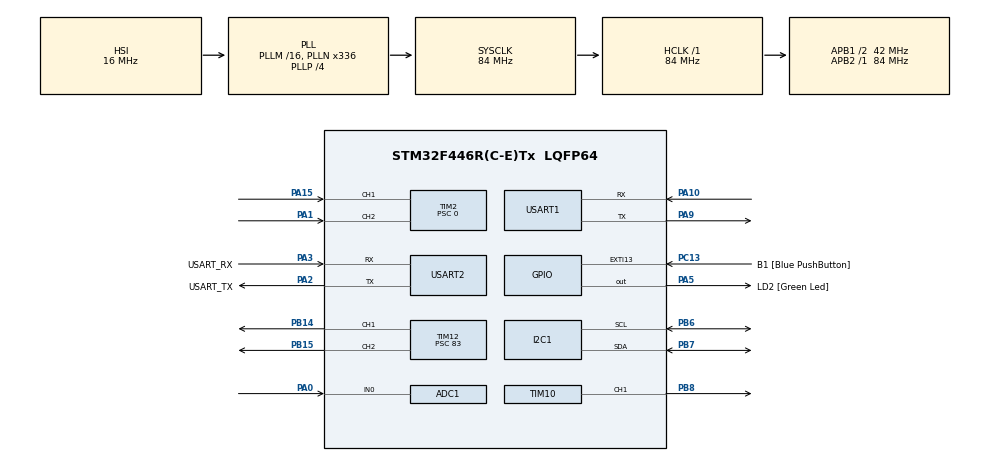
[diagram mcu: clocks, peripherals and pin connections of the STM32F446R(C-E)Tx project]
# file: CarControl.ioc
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ADC1.Channel-0\#ChannelRegularConversion=ADC_CHANNEL_0
ADC1.ContinuousConvMode=DISABLE
ADC1.ExternalTrigConv=ADC_EXTERNALTRIGCONV_T3_TRGO
ADC1.NbrOfConversionFlag=1
ADC1.Rank-0\#ChannelRegularConversion=1
ADC1.SamplingTime-0\#ChannelRegularConversion=ADC_SAMPLETIME_3CYCLES
ADC1.master=1
Dma.ADC1.0.Direction=DMA_PERIPH_TO_MEMORY
Dma.ADC1.0.FIFOMode=DMA_FIFOMODE_DISABLE
Dma.ADC1.0.Instance=DMA2_Stream0
Dma.ADC1.0.MemDataAlignment=DMA_MDATAALIGN_HALFWORD
Dma.ADC1.0.MemInc=DMA_MINC_ENABLE
Dma.ADC1.0.Mode=DMA_CIRCULAR
Dma.ADC1.0.PeriphDataAlignment=DMA_PDATAALIGN_HALFWORD
Dma.ADC1.0.PeriphInc=DMA_PINC_DISABLE
Dma.ADC1.0.Priority=DMA_PRIORITY_LOW
Dma.Request0=ADC1
Dma.Request1=USART1_RX
Dma.Request2=USART1_TX
Dma.USART1_RX.1.Direction=DMA_PERIPH_TO_MEMORY
Dma.USART1_RX.1.FIFOMode=DMA_FIFOMODE_DISABLE
Dma.USART1_RX.1.Instance=DMA2_Stream2
Dma.USART1_RX.1.MemDataAlignment=DMA_MDATAALIGN_BYTE
Dma.USART1_RX.1.MemInc=DMA_MINC_ENABLE
Dma.USART1_RX.1.Mode=DMA_CIRCULAR
Dma.USART1_RX.1.PeriphDataAlignment=DMA_PDATAALIGN_BYTE
Dma.USART1_RX.1.PeriphInc=DMA_PINC_DISABLE
Dma.USART1_RX.1.Priority=DMA_PRIORITY_HIGH
Dma.USART1_TX.2.Direction=DMA_MEMORY_TO_PERIPH
Dma.USART1_TX.2.FIFOMode=DMA_FIFOMODE_DISABLE
Dma.USART1_TX.2.Instance=DMA2_Stream7
Dma.USART1_TX.2.MemDataAlignment=DMA_MDATAALIGN_BYTE
Dma.USART1_TX.2.MemInc=DMA_MINC_ENABLE
Dma.USART1_TX.2.Mode=DMA_NORMAL
Dma.USART1_TX.2.PeriphDataAlignment=DMA_PDATAALIGN_BYTE
Dma.USART1_TX.2.PeriphInc=DMA_PINC_DISABLE
Dma.USART1_TX.2.Priority=DMA_PRIORITY_HIGH
FREERTOS.Tasks01=defaultTask,24,128,RunDefaultTask,Default,NULL,Dynamic,NULL,NULL;ControlTask,40,512,RunControlTask,Default,NULL,Dynamic,NULL,NULL;SensorTask,24,512,RunSensorTask,Default,NULL,Dynamic,NULL,NULL;StatusTask,8,512,RunStatusTask,Default,NULL,Dynamic,NULL,NULL;microROSTask,24,1024,RunMicroROSTask,Default,NULL,Dynamic,NULL,NULL
FREERTOS.configENABLE_FPU=1
FREERTOS.configTOTAL_HEAP_SIZE=32768
FREERTOS.configUSE_NEWLIB_REENTRANT=1
Mcu.Family=STM32F4
Mcu.Name=STM32F446R(C-E)Tx
Mcu.Package=LQFP64
NVIC.DMA2_Stream0_IRQn=true\:5\:0\:false\:false\:true\:true\:false\:true\:true
NVIC.DMA2_Stream2_IRQn=true\:5\:0\:false\:false\:true\:true\:false\:true\:true
NVIC.DMA2_Stream7_IRQn=true\:5\:0\:false\:false\:true\:true\:false\:true\:true
NVIC.PriorityGroup=NVIC_PRIORITYGROUP_4
NVIC.TIM3_IRQn=true\:5\:0\:false\:false\:true\:true\:true\:true\:true
NVIC.TIM6_DAC_IRQn=true\:15\:0\:false\:false\:true\:false\:false\:true\:true
NVIC.TimeBase=TIM6_DAC_IRQn
NVIC.TimeBaseIP=TIM6
NVIC.USART1_IRQn=true\:5\:0\:false\:false\:true\:true\:true\:true\:true
PA0-WKUP.Signal=ADCx_IN0
PA1.Signal=S_TIM2_CH2
PA10.Mode=Asynchronous
PA10.Signal=USART1_RX
PA13.GPIO_Label=TMS
PA13.Mode=Serial_Wire
PA13.Signal=SYS_JTMS-SWDIO
PA14.GPIO_Label=TCK
PA14.Mode=Serial_Wire
PA14.Signal=SYS_JTCK-SWCLK
PA15.Signal=S_TIM2_CH1_ETR
PA2.GPIO_Label=USART_TX
PA2.Mode=Asynchronous
PA2.Signal=USART2_TX
PA3.GPIO_Label=USART_RX
PA3.Mode=Asynchronous
PA3.Signal=USART2_RX
PA5.GPIO_Label=LD2 [Green Led]
PA5.Signal=GPIO_Output
PA9.Mode=Asynchronous
PA9.Signal=USART1_TX
PB14.Signal=S_TIM12_CH1
PB15.Signal=S_TIM12_CH2
PB3.GPIO_Label=SWO
PB3.Signal=SYS_JTDO-SWO
PB6.Mode=I2C
PB6.Signal=I2C1_SCL
PB7.Mode=I2C
PB7.Signal=I2C1_SDA
PB8.Signal=S_TIM10_CH1
PC13.GPIO_Label=B1 [Blue PushButton]
PC13.GPIO_ModeDefaultEXTI=GPIO_MODE_IT_FALLING
PC13.Signal=GPXTI13
PC14-OSC32_IN.Mode=LSE-External-Oscillator
PC14-OSC32_IN.Signal=RCC_OSC32_IN
PC15-OSC32_OUT.Mode=LSE-External-Oscillator
PC15-OSC32_OUT.Signal=RCC_OSC32_OUT
PH0-OSC_IN.Mode=HSE-External-Oscillator
PH0-OSC_IN.Signal=RCC_OSC_IN
PH1-OSC_OUT.Mode=HSE-External-Oscillator
PH1-OSC_OUT.Signal=RCC_OSC_OUT
ProjectManager.HeapSize=0x200
ProjectManager.StackSize=0x400
ProjectManager.TargetToolchain=Makefile
RCC.48MHZClocksFreq_Value=84000000
RCC.AHBFreq_Value=84000000
RCC.APB1CLKDivider=RCC_HCLK_DIV2
RCC.APB1Freq_Value=42000000
RCC.APB1TimFreq_Value=84000000
RCC.APB2Freq_Value=84000000
RCC.APB2TimFreq_Value=84000000
RCC.CortexFreq_Value=84000000
RCC.FLatency-AdvancedSettings=FLASH_LATENCY_2
RCC.HCLKFreq_Value=84000000
RCC.HSE_VALUE=8000000
RCC.HSI_VALUE=16000000
RCC.PLLN=336
RCC.PLLP=RCC_PLLP_DIV4
RCC.SYSCLKFreq_VALUE=84000000
RCC.SYSCLKSource=RCC_SYSCLKSOURCE_PLLCLK
RCC.USBFreq_Value=168000000
RCC.VCOOutputFreq_Value=336000000
SH.ADCx_IN0.0=ADC1_IN0,IN0
SH.S_TIM10_CH1.0=TIM10_CH1,PWM Generation1 CH1
SH.S_TIM12_CH1.0=TIM12_CH1,PWM Generation1 CH1
SH.S_TIM12_CH2.0=TIM12_CH2,PWM Generation2 CH2
SH.S_TIM2_CH1_ETR.0=TIM2_CH1,Encoder_Interface
SH.S_TIM2_CH2.0=TIM2_CH2,Encoder_Interface
TIM10.Channel=TIM_CHANNEL_1
TIM10.Period=49
TIM10.Prescaler=83
TIM10.Pulse=0
TIM12.Channel-PWM\ Generation1\ CH1=TIM_CHANNEL_1
TIM12.Channel-PWM\ Generation2\ CH2=TIM_CHANNEL_2
TIM12.Period=49
TIM12.Prescaler=83
TIM2.EncoderMode=TIM_ENCODERMODE_TI12
TIM2.Period=1000
TIM2.Prescaler=0
TIM3.Channel-Output\ Compare1\ No\ Output=TIM_CHANNEL_1
TIM3.Period=999
TIM3.Prescaler=839
TIM3.TIM_MasterOutputTrigger=TIM_TRGO_UPDATE
USART1.VirtualMode=VM_ASYNC
USART2.VirtualMode=VM_ASYNC
VP_FREERTOS_VS_CMSIS_V2.Mode=CMSIS_V2
VP_SYS_VS_tim6.Mode=TIM6
VP_TIM10_VS_ClockSourceINT.Mode=Enable_Timer
VP_TIM3_VS_ClockSourceINT.Mode=Internal
VP_TIM3_VS_no_output1.Mode=Output Compare1 No Output
board=NUCLEO-F446RE

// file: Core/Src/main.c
/* USER CODE BEGIN Header */
/**
  ******************************************************************************
  * @file           : main.c
  * @brief          : Main program body
  ******************************************************************************
  * @attention
  *
  * Copyright (c) 2026 STMicroelectronics.
  * All rights reserved.
  *
  * This software is licensed under terms that can be found in the LICENSE file
  * in the root directory of this software component.
  * If no LICENSE file comes with this software, it is provided AS-IS.
  *
  ******************************************************************************
  */
/* USER CODE END Header */
#include "main.h"
#include "cmsis_os.h"

/* USER CODE BEGIN Includes */
#include "mros.h"
#include "main_app.hpp"
/* USER CODE END Includes */

ADC_HandleTypeDef hadc1;
DMA_HandleTypeDef hdma_adc1;

I2C_HandleTypeDef hi2c1;

TIM_HandleTypeDef htim2;
TIM_HandleTypeDef htim3;
TIM_HandleTypeDef htim10;
TIM_HandleTypeDef htim12;

UART_HandleTypeDef huart1;
UART_HandleTypeDef huart2;
DMA_HandleTypeDef hdma_usart1_rx;
DMA_HandleTypeDef hdma_usart1_tx;

/* Definitions for defaultTask */
osThreadId_t defaultTaskHandle;
const osThreadAttr_t defaultTask_attributes = {
  .name = "defaultTask",
  .stack_size = 128 * 4,
  .priority = (osPriority_t) osPriorityNormal,
};
/* Definitions for ControlTask */
osThreadId_t ControlTaskHandle;
const osThreadAttr_t ControlTask_attributes = {
  .name = "ControlTask",
  .stack_size = 512 * 4,
  .priority = (osPriority_t) osPriorityHigh,
};
/* Definitions for SensorTask */
osThreadId_t SensorTaskHandle;
const osThreadAttr_t SensorTask_attributes = {
  .name = "SensorTask",
  .stack_size = 512 * 4,
  .priority = (osPriority_t) osPriorityNormal,
};
/* Definitions for StatusTask */
osThreadId_t StatusTaskHandle;
const osThreadAttr_t StatusTask_attributes = {
  .name = "StatusTask",
  .stack_size = 512 * 4,
  .priority = (osPriority_t) osPriorityLow,
};
/* Definitions for microROSTask */
osThreadId_t microROSTaskHandle;
const osThreadAttr_t microROSTask_attributes = {
  .name = "microROSTask",
  .stack_size = 1024 * 4,
  .priority = (osPriority_t) osPriorityNormal,
};

void SystemClock_Config(void);
static void MX_GPIO_Init(void);
static void MX_DMA_Init(void);
static void MX_I2C1_Init(void);
static void MX_USART2_UART_Init(void);
static void MX_TIM3_Init(void);
static void MX_TIM2_Init(void);
static void MX_TIM10_Init(void);
static void MX_TIM12_Init(void);
static void MX_ADC1_Init(void);
static void MX_USART1_UART_Init(void);
void RunDefaultTask(void *argument);
void RunControlTask(void *argument);
void RunSensorTask(void *argument);
void RunStatusTask(void *argument);
void RunMicroROSTask(void *argument);

int main(void)
{

  /* MCU Configuration--------------------------------------------------------*/

  /* Reset of all peripherals, Initializes the Flash interface and the Systick. */
  HAL_Init();

  /* Configure the system clock */
  SystemClock_Config();

  /* Initialize all configured peripherals */
  MX_GPIO_Init();
  MX_DMA_Init();
  MX_I2C1_Init();
  MX_USART2_UART_Init();
  MX_TIM3_Init();
  MX_TIM2_Init();
  MX_TIM10_Init();
  MX_TIM12_Init();
  MX_ADC1_Init();
  MX_USART1_UART_Init();

  /* Init scheduler */
  osKernelInitialize();

  /* USER CODE BEGIN RTOS_MUTEX */
  main_init();
  /* add mutexes, ... */
  /* USER CODE END RTOS_MUTEX */

  /* Create the thread(s) */
  /* creation of defaultTask */
  defaultTaskHandle = osThreadNew(RunDefaultTask, NULL, &defaultTask_attributes);

  /* creation of ControlTask */
  ControlTaskHandle = osThreadNew(RunControlTask, NULL, &ControlTask_attributes);

  /* creation of SensorTask */
  SensorTaskHandle = osThreadNew(RunSensorTask, NULL, &SensorTask_attributes);

  /* creation of StatusTask */
  StatusTaskHandle = osThreadNew(RunStatusTask, NULL, &StatusTask_attributes);

  /* creation of microROSTask */
  microROSTaskHandle = osThreadNew(RunMicroROSTask, NULL, &microROSTask_attributes);

  /* Start scheduler */
  osKernelStart();

  /* We should never get here as control is now taken by the scheduler */

  /* Infinite loop */
  while (1)
  {

  }
}

void SystemClock_Config(void)
{
  RCC_OscInitTypeDef RCC_OscInitStruct = {0};
  RCC_ClkInitTypeDef RCC_ClkInitStruct = {0};

  /** Configure the main internal regulator output voltage
  */
  __HAL_RCC_PWR_CLK_ENABLE();
  __HAL_PWR_VOLTAGESCALING_CONFIG(PWR_REGULATOR_VOLTAGE_SCALE3);

  /** Initializes the RCC Oscillators according to the specified parameters
  * in the RCC_OscInitTypeDef structure.
  */
  RCC_OscInitStruct.OscillatorType = RCC_OSCILLATORTYPE_HSI;
  RCC_OscInitStruct.HSIState = RCC_HSI_ON;
  RCC_OscInitStruct.HSICalibrationValue = RCC_HSICALIBRATION_DEFAULT;
  RCC_OscInitStruct.PLL.PLLState = RCC_PLL_ON;
  RCC_OscInitStruct.PLL.PLLSource = RCC_PLLSOURCE_HSI;
  RCC_OscInitStruct.PLL.PLLM = 16;
  RCC_OscInitStruct.PLL.PLLN = 336;
  RCC_OscInitStruct.PLL.PLLP = RCC_PLLP_DIV4;
  RCC_OscInitStruct.PLL.PLLQ = 2;
  RCC_OscInitStruct.PLL.PLLR = 2;
  if (HAL_RCC_OscConfig(&RCC_OscInitStruct) != HAL_OK)
  {
    Error_Handler();
  }

  /** Initializes the CPU, AHB and APB buses clocks
  */
  RCC_ClkInitStruct.ClockType = RCC_CLOCKTYPE_HCLK|RCC_CLOCKTYPE_SYSCLK
                              |RCC_CLOCKTYPE_PCLK1|RCC_CLOCKTYPE_PCLK2;
  RCC_ClkInitStruct.SYSCLKSource = RCC_SYSCLKSOURCE_PLLCLK;
  RCC_ClkInitStruct.AHBCLKDivider = RCC_SYSCLK_DIV1;
  RCC_ClkInitStruct.APB1CLKDivider = RCC_HCLK_DIV2;
  RCC_ClkInitStruct.APB2CLKDivider = RCC_HCLK_DIV1;

  if (HAL_RCC_ClockConfig(&RCC_ClkInitStruct, FLASH_LATENCY_2) != HAL_OK)
  {
    Error_Handler();
  }
}

static void MX_ADC1_Init(void)
{

  ADC_ChannelConfTypeDef sConfig = {0};

  /** Configure the global features of the ADC (Clock, Resolution, Data Alignment and number of conversion)
  */
  hadc1.Instance = ADC1;
  hadc1.Init.ClockPrescaler = ADC_CLOCK_SYNC_PCLK_DIV4;
  hadc1.Init.Resolution = ADC_RESOLUTION_12B;
  hadc1.Init.ScanConvMode = DISABLE;
  hadc1.Init.ContinuousConvMode = DISABLE;
  hadc1.Init.DiscontinuousConvMode = DISABLE;
  hadc1.Init.ExternalTrigConvEdge = ADC_EXTERNALTRIGCONVEDGE_RISING;
  hadc1.Init.ExternalTrigConv = ADC_EXTERNALTRIGCONV_T3_TRGO;
  hadc1.Init.DataAlign = ADC_DATAALIGN_RIGHT;
  hadc1.Init.NbrOfConversion = 1;
  hadc1.Init.DMAContinuousRequests = DISABLE;
  hadc1.Init.EOCSelection = ADC_EOC_SINGLE_CONV;
  if (HAL_ADC_Init(&hadc1) != HAL_OK)
  {
    Error_Handler();
  }

  /** Configure for the selected ADC regular channel its corresponding rank in the sequencer and its sample time.
  */
  sConfig.Channel = ADC_CHANNEL_0;
  sConfig.Rank = 1;
  sConfig.SamplingTime = ADC_SAMPLETIME_3CYCLES;
  if (HAL_ADC_ConfigChannel(&hadc1, &sConfig) != HAL_OK)
  {
    Error_Handler();
  }

}

static void MX_I2C1_Init(void)
{

  hi2c1.Instance = I2C1;
  hi2c1.Init.ClockSpeed = 100000;
  hi2c1.Init.DutyCycle = I2C_DUTYCYCLE_2;
  hi2c1.Init.OwnAddress1 = 0;
  hi2c1.Init.AddressingMode = I2C_ADDRESSINGMODE_7BIT;
  hi2c1.Init.DualAddressMode = I2C_DUALADDRESS_DISABLE;
  hi2c1.Init.OwnAddress2 = 0;
  hi2c1.Init.GeneralCallMode = I2C_GENERALCALL_DISABLE;
  hi2c1.Init.NoStretchMode = I2C_NOSTRETCH_DISABLE;
  if (HAL_I2C_Init(&hi2c1) != HAL_OK)
  {
    Error_Handler();
  }

}

static void MX_TIM2_Init(void)
{

  TIM_Encoder_InitTypeDef sConfig = {0};
  TIM_MasterConfigTypeDef sMasterConfig = {0};

  htim2.Instance = TIM2;
  htim2.Init.Prescaler = 0;
  htim2.Init.CounterMode = TIM_COUNTERMODE_UP;
  htim2.Init.Period = 1000;
  htim2.Init.ClockDivision = TIM_CLOCKDIVISION_DIV1;
  htim2.Init.AutoReloadPreload = TIM_AUTORELOAD_PRELOAD_DISABLE;
  sConfig.EncoderMode = TIM_ENCODERMODE_TI12;
  sConfig.IC1Polarity = TIM_ICPOLARITY_RISING;
  sConfig.IC1Selection = TIM_ICSELECTION_DIRECTTI;
  sConfig.IC1Prescaler = TIM_ICPSC_DIV1;
  sConfig.IC1Filter = 0;
  sConfig.IC2Polarity = TIM_ICPOLARITY_RISING;
  sConfig.IC2Selection = TIM_ICSELECTION_DIRECTTI;
  sConfig.IC2Prescaler = TIM_ICPSC_DIV1;
  sConfig.IC2Filter = 0;
  if (HAL_TIM_Encoder_Init(&htim2, &sConfig) != HAL_OK)
  {
    Error_Handler();
  }
  sMasterConfig.MasterOutputTrigger = TIM_TRGO_RESET;
  sMasterConfig.MasterSlaveMode = TIM_MASTERSLAVEMODE_DISABLE;
  if (HAL_TIMEx_MasterConfigSynchronization(&htim2, &sMasterConfig) != HAL_OK)
  {
    Error_Handler();
  }

}

static void MX_TIM3_Init(void)
{

  TIM_ClockConfigTypeDef sClockSourceConfig = {0};
  TIM_MasterConfigTypeDef sMasterConfig = {0};
  TIM_OC_InitTypeDef sConfigOC = {0};

  htim3.Instance = TIM3;
  htim3.Init.Prescaler = 839;
  htim3.Init.CounterMode = TIM_COUNTERMODE_UP;
  htim3.Init.Period = 999;
  htim3.Init.ClockDivision = TIM_CLOCKDIVISION_DIV1;
  htim3.Init.AutoReloadPreload = TIM_AUTORELOAD_PRELOAD_DISABLE;
  if (HAL_TIM_Base_Init(&htim3) != HAL_OK)
  {
    Error_Handler();
  }
  sClockSourceConfig.ClockSource = TIM_CLOCKSOURCE_INTERNAL;
  if (HAL_TIM_ConfigClockSource(&htim3, &sClockSourceConfig) != HAL_OK)
  {
    Error_Handler();
  }
  if (HAL_TIM_OC_Init(&htim3) != HAL_OK)
  {
    Error_Handler();
  }
  sMasterConfig.MasterOutputTrigger = TIM_TRGO_UPDATE;
  sMasterConfig.MasterSlaveMode = TIM_MASTERSLAVEMODE_DISABLE;
  if (HAL_TIMEx_MasterConfigSynchronization(&htim3, &sMasterConfig) != HAL_OK)
  {
    Error_Handler();
  }
  sConfigOC.OCMode = TIM_OCMODE_TIMING;
  sConfigOC.Pulse = 0;
  sConfigOC.OCPolarity = TIM_OCPOLARITY_HIGH;
  sConfigOC.OCFastMode = TIM_OCFAST_DISABLE;
  if (HAL_TIM_OC_ConfigChannel(&htim3, &sConfigOC, TIM_CHANNEL_1) != HAL_OK)
  {
    Error_Handler();
  }

}

static void MX_TIM10_Init(void)
{

  TIM_OC_InitTypeDef sConfigOC = {0};

  htim10.Instance = TIM10;
  htim10.Init.Prescaler = 83;
  htim10.Init.CounterMode = TIM_COUNTERMODE_UP;
  htim10.Init.Period = 49;
  htim10.Init.ClockDivision = TIM_CLOCKDIVISION_DIV1;
  htim10.Init.AutoReloadPreload = TIM_AUTORELOAD_PRELOAD_DISABLE;
  if (HAL_TIM_Base_Init(&htim10) != HAL_OK)
  {
    Error_Handler();
  }
  if (HAL_TIM_PWM_Init(&htim10) != HAL_OK)
  {
    Error_Handler();
  }
  sConfigOC.OCMode = TIM_OCMODE_PWM1;
  sConfigOC.Pulse = 0;
  sConfigOC.OCPolarity = TIM_OCPOLARITY_HIGH;
  sConfigOC.OCFastMode = TIM_OCFAST_DISABLE;
  if (HAL_TIM_PWM_ConfigChannel(&htim10, &sConfigOC, TIM_CHANNEL_1) != HAL_OK)
  {
    Error_Handler();
  }
  HAL_TIM_MspPostInit(&htim10);

}

static void MX_TIM12_Init(void)
{

  TIM_OC_InitTypeDef sConfigOC = {0};

  htim12.Instance = TIM12;
  htim12.Init.Prescaler = 83;
  htim12.Init.CounterMode = TIM_COUNTERMODE_UP;
  htim12.Init.Period = 49;
  htim12.Init.ClockDivision = TIM_CLOCKDIVISION_DIV1;
  htim12.Init.AutoReloadPreload = TIM_AUTORELOAD_PRELOAD_DISABLE;
  if (HAL_TIM_PWM_Init(&htim12) != HAL_OK)
  {
    Error_Handler();
  }
  sConfigOC.OCMode = TIM_OCMODE_PWM1;
  sConfigOC.Pulse = 0;
  sConfigOC.OCPolarity = TIM_OCPOLARITY_HIGH;
  sConfigOC.OCFastMode = TIM_OCFAST_DISABLE;
  if (HAL_TIM_PWM_ConfigChannel(&htim12, &sConfigOC, TIM_CHANNEL_1) != HAL_OK)
  {
    Error_Handler();
  }
  if (HAL_TIM_PWM_ConfigChannel(&htim12, &sConfigOC, TIM_CHANNEL_2) != HAL_OK)
  {
    Error_Handler();
  }
  HAL_TIM_MspPostInit(&htim12);

}

static void MX_USART1_UART_Init(void)
{

  huart1.Instance = USART1;
  huart1.Init.BaudRate = 115200;
  huart1.Init.WordLength = UART_WORDLENGTH_8B;
  huart1.Init.StopBits = UART_STOPBITS_1;
  huart1.Init.Parity = UART_PARITY_NONE;
  huart1.Init.Mode = UART_MODE_TX_RX;
  huart1.Init.HwFlowCtl = UART_HWCONTROL_NONE;
  huart1.Init.OverSampling = UART_OVERSAMPLING_16;
  if (HAL_UART_Init(&huart1) != HAL_OK)
  {
    Error_Handler();
  }

}

static void MX_USART2_UART_Init(void)
{

  huart2.Instance = USART2;
  huart2.Init.BaudRate = 115200;
  huart2.Init.WordLength = UART_WORDLENGTH_8B;
  huart2.Init.StopBits = UART_STOPBITS_1;
  huart2.Init.Parity = UART_PARITY_NONE;
  huart2.Init.Mode = UART_MODE_TX_RX;
  huart2.Init.HwFlowCtl = UART_HWCONTROL_NONE;
  huart2.Init.OverSampling = UART_OVERSAMPLING_16;
  if (HAL_UART_Init(&huart2) != HAL_OK)
  {
    Error_Handler();
  }

}

static void MX_DMA_Init(void)
{

  /* DMA controller clock enable */
  __HAL_RCC_DMA2_CLK_ENABLE();

  /* DMA interrupt init */
  /* DMA2_Stream0_IRQn interrupt configuration */
  HAL_NVIC_SetPriority(DMA2_Stream0_IRQn, 5, 0);
  HAL_NVIC_EnableIRQ(DMA2_Stream0_IRQn);
  /* DMA2_Stream2_IRQn interrupt configuration */
  HAL_NVIC_SetPriority(DMA2_Stream2_IRQn, 5, 0);
  HAL_NVIC_EnableIRQ(DMA2_Stream2_IRQn);
  /* DMA2_Stream7_IRQn interrupt configuration */
  HAL_NVIC_SetPriority(DMA2_Stream7_IRQn, 5, 0);
  HAL_NVIC_EnableIRQ(DMA2_Stream7_IRQn);

}

static void MX_GPIO_Init(void)
{
  GPIO_InitTypeDef GPIO_InitStruct = {0};

  /* GPIO Ports Clock Enable */
  __HAL_RCC_GPIOC_CLK_ENABLE();
  __HAL_RCC_GPIOH_CLK_ENABLE();
  __HAL_RCC_GPIOA_CLK_ENABLE();
  __HAL_RCC_GPIOB_CLK_ENABLE();

  /*Configure GPIO pin Output Level */
  HAL_GPIO_WritePin(LD2_GPIO_Port, LD2_Pin, GPIO_PIN_RESET);

  /*Configure GPIO pin : B1_Pin */
  GPIO_InitStruct.Pin = B1_Pin;
  GPIO_InitStruct.Mode = GPIO_MODE_IT_FALLING;
  GPIO_InitStruct.Pull = GPIO_NOPULL;
  HAL_GPIO_Init(B1_GPIO_Port, &GPIO_InitStruct);

  /*Configure GPIO pin : LD2_Pin */
  GPIO_InitStruct.Pin = LD2_Pin;
  GPIO_InitStruct.Mode = GPIO_MODE_OUTPUT_PP;
  GPIO_InitStruct.Pull = GPIO_NOPULL;
  GPIO_InitStruct.Speed = GPIO_SPEED_FREQ_LOW;
  HAL_GPIO_Init(LD2_GPIO_Port, &GPIO_InitStruct);

}

void RunDefaultTask(void *argument)
{
  for(;;)
  {
    osDelay(1);
  }
}

void RunControlTask(void *argument)
{
  /* USER CODE BEGIN RunControlTask */
  runPeriodicTask(controlTask, argument, 100);

  /* USER CODE END RunControlTask */
}

void RunSensorTask(void *argument)
{
  /* USER CODE BEGIN RunSensorTask */
  runPeriodicTask(sensorTask, argument, 100);
  /* USER CODE END RunSensorTask */
}

void RunStatusTask(void *argument)
{
  /* USER CODE BEGIN RunStatusTask */
  /* Infinite loop */
  runPeriodicTask(statusTask, argument, 1000);
  /* USER CODE END RunStatusTask */
}

void RunMicroROSTask(void *argument)
{
  /* USER CODE BEGIN RunMicroROSTask */
  // start micro ROS
  init_mros();
  /* Infinite loop */
  runPeriodicTask(microROSTask, argument, 100);
  /* USER CODE END RunMicroROSTask */
}

void HAL_TIM_PeriodElapsedCallback(TIM_HandleTypeDef *htim)
{
  if (htim->Instance == TIM6)
  {
    HAL_IncTick();
  }
}

void Error_Handler(void)
{
  __disable_irq();
  while (1)
  {
  }
}
